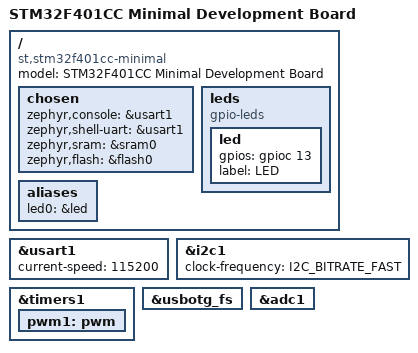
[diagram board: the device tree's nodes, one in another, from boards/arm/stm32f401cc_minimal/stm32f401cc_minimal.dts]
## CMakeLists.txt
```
cmake_minimum_required(VERSION 3.13.1)

set(BOARD_ROOT ${CMAKE_CURRENT_LIST_DIR})
set(BOARD stm32f401cc_minimal)

find_package(Zephyr REQUIRED HINTS $ENV{ZEPHYR_BASE})
project(stm32f401cc_boardtest)

target_sources(app PRIVATE src/main.c)
```

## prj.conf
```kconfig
CONFIG_LOG=y
CONFIG_PRINTK=y
CONFIG_SHELL=y
CONFIG_BOOT_BANNER=y
CONFIG_KERNEL_SHELL=y
CONFIG_DEVICE_SHELL=y
CONFIG_THREAD_MONITOR=y
CONFIG_DATE_SHELL=y
CONFIG_POSIX_CLOCK=y
```

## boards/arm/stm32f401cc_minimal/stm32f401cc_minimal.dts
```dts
/dts-v1/;
#include <st/f4/stm32f401Xc.dtsi>

/ {
	model = "STM32F401CC Minimal Development Board";
	compatible = "st,stm32f401cc-minimal", "st,stm32f401";

	chosen {
		zephyr,console = &usart1;
		zephyr,shell-uart = &usart1;
		zephyr,sram = &sram0;
		zephyr,flash = &flash0;
		//zephyr,ccm = &ccm0;
	};

	leds { 
		compatible = "gpio-leds";
		led: led {
			gpios = <&gpioc 13 GPIO_ACTIVE_HIGH>;
			label = "LED";
		};
	};
	aliases {
		led0 = &led;
	};
};

&usart1 {
	current-speed = <115200>;
	status = "okay";
};

&i2c1 {
	status = "okay";
	clock-frequency = <I2C_BITRATE_FAST>;
};

&timers1 {
	status = "okay";
	pwm1: pwm {
		status = "okay";
	};
};

&usbotg_fs {
	status = "okay";
};
&adc1 {
	status = "okay";
};
```

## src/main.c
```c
#include <zephyr.h>
#include <sys/printk.h>
#include <shell/shell.h>
#include <shell/shell_uart.h>
#include <version.h>
#include <logging/log.h>
#include <stdlib.h>

LOG_MODULE_REGISTER(app);

static int cmd_demo_ping(const struct shell *shell, size_t argc, char **argv){
	ARG_UNUSED(argc);
	ARG_UNUSED(argv);

	shell_print(shell, "pong");

	return 0;
}

static int cmd_version(const struct shell *shell, size_t argc, char **argv){
	ARG_UNUSED(argc);
	ARG_UNUSED(argv);

	shell_print(shell, "Zephyr version %s", KERNEL_VERSION_STRING);

	return 0;
}

SHELL_STATIC_SUBCMD_SET_CREATE(sub_demo,
	SHELL_CMD(ping, NULL, "Ping command.", cmd_demo_ping),
	SHELL_SUBCMD_SET_END /* Array terminated */
);
SHELL_CMD_REGISTER(demo, &sub_demo, "Demo commands", NULL);
SHELL_CMD_ARG_REGISTER(version, NULL, "Show kernel version", cmd_version, 1, 0);

void main(void){
	// do nothing
}
```
